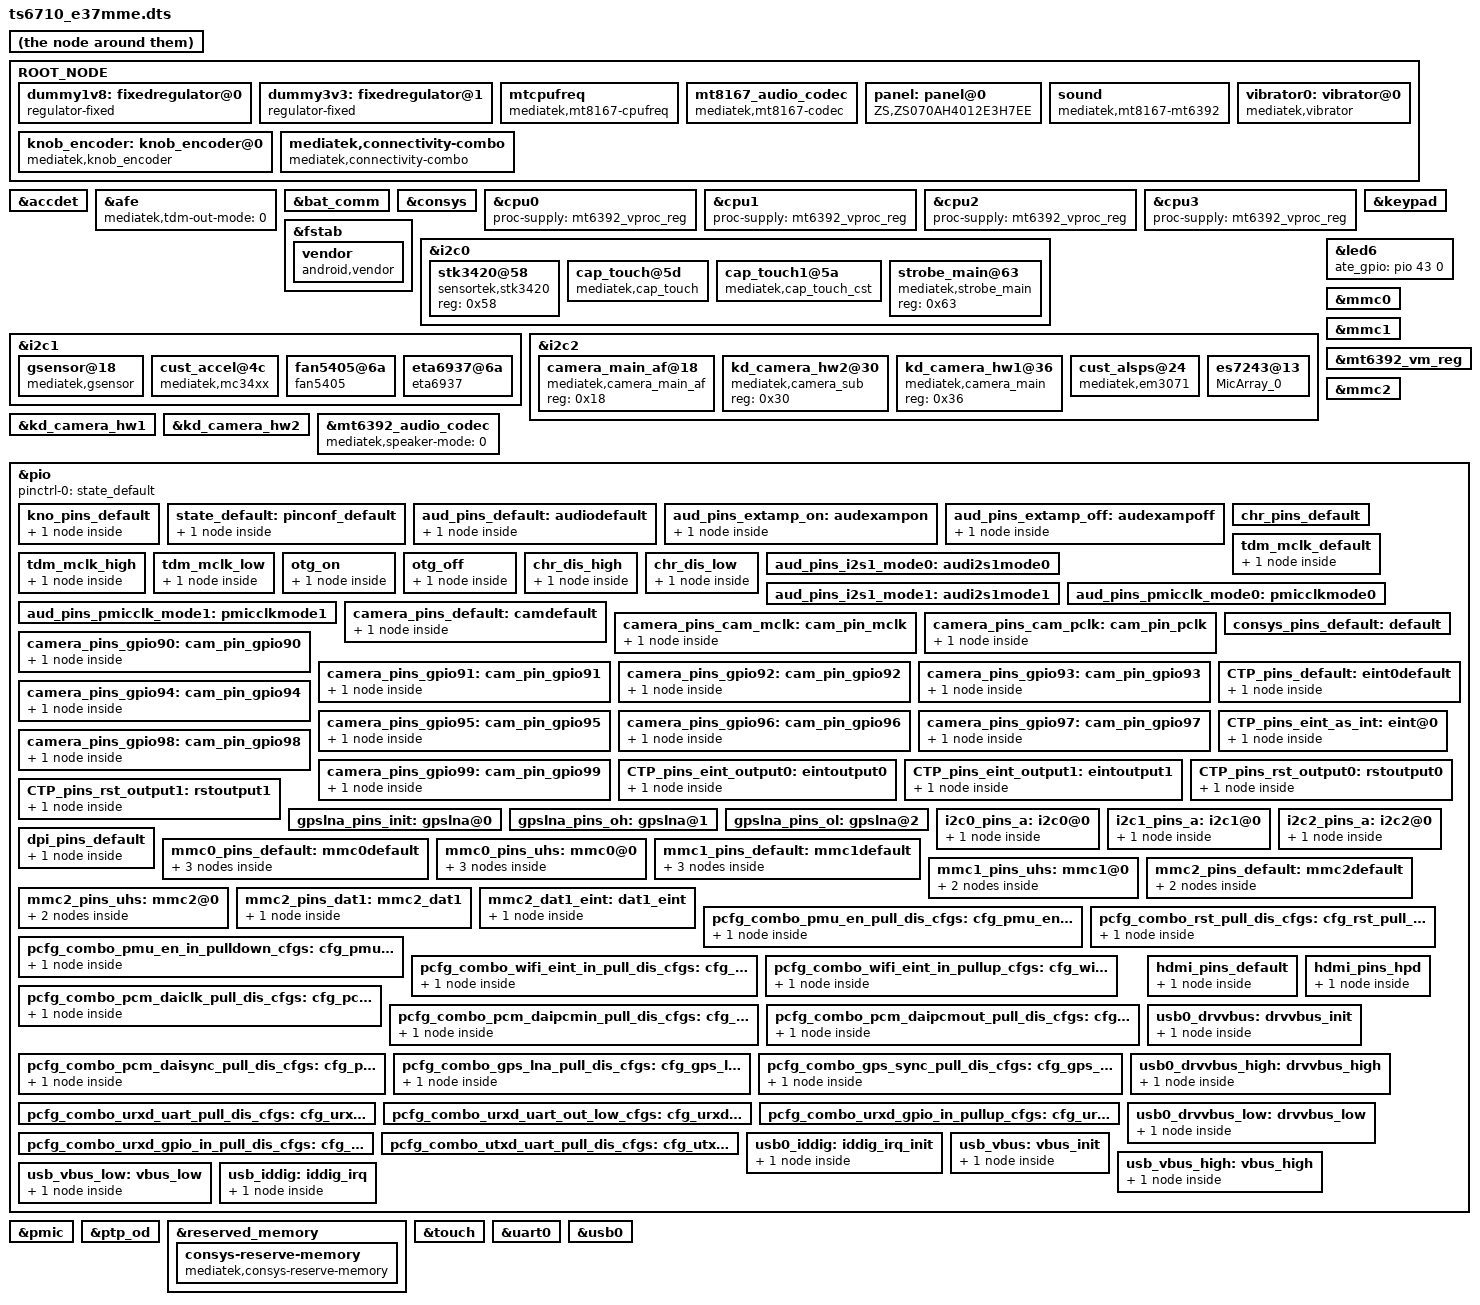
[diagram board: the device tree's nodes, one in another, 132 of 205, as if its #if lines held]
/*
 * Copyright (c) 2014-2015 MediaTek Inc.
 *
 * This program is free software; you can redistribute it and/or modify
 * it under the terms of the GNU General Public License version 2 as
 * published by the Free Software Foundation.
 *
 * This program is distributed in the hope that it will be useful,
 * MERCHANTABILITY or FITNESS FOR A PARTICULAR PURPOSE.  See the
 * GNU General Public License for more details.
 */

#include <generated/autoconf.h>
/dts-v1/;

#ifdef CONFIG_MTK_DTBO_FEATURE
/plugin/;
#include <dt-bindings/clock/mt8167-clk.h>
#include <dt-bindings/interrupt-controller/irq.h>
#include <dt-bindings/interrupt-controller/arm-gic.h>
#include "mt8167-pinfunc.h"
#define ROOT_NODE &odm
#else
#include "mt8167.dtsi"
#include "mt6392.dtsi"
#define ROOT_NODE /
#endif
#include "ts6710_e37mme_bat_setting.dtsi"
#include <dt-bindings/gpio/gpio.h>

ROOT_NODE {
	dummy1v8: fixedregulator@0 {
		compatible = "regulator-fixed";
		regulator-name = "mmc_io";
		regulator-min-microvolt = <1800000>;
		regulator-max-microvolt = <1800000>;
		regulator-always-on;
	};

	dummy3v3: fixedregulator@1 {
		compatible = "regulator-fixed";
		regulator-name = "mmc_power";
		regulator-min-microvolt = <3300000>;
		regulator-max-microvolt = <3300000>;
		regulator-always-on;
	};

	mtcpufreq {
		compatible = "mediatek,mt8167-cpufreq";
	};

	mt8167_audio_codec: mt8167_audio_codec {
		compatible = "mediatek,mt8167-codec";
		clocks = <&topckgen CLK_TOP_AUDIO>;
		clock-names = "bus";
		mediatek,afe-regmap = <&afe>;
		mediatek,apmixedsys-regmap = <&apmixedsys>;
		mediatek,dmic-wire-mode = <1>; /* 0(ONE_WIRE) 1(TWO_WIRE) */
		mediatek,headphone-cap-sel = <1>; /* 0(10UF) 1(22UF) 2(33UF) 3(47UF) */
	};

	panel: panel@0 {
		compatible = "ZS,ZS070AH4012E3H7EE";
		pinctrl-names = "default";
		pinctrl-0 = <&dpi_pins_default>;
		gpio_lcd_pwr = <&pio 50 0>;
		gpio_lcd_rst = <&pio 66 0>;
		reg-lcm-supply = <&mt6392_vgp2_reg>;
		status = "okay";
	};

	sound: sound {
		compatible = "mediatek,mt8167-mt6392";
		mediatek,platform = <&afe>;
		mediatek,hp-spk-amp-warmup-time-us = <40000>;
		pinctrl-names = "default", "extamp_on", "extamp_off";
		pinctrl-0 = <&aud_pins_default>;
		pinctrl-1 = <&aud_pins_extamp_on>;
		pinctrl-2 = <&aud_pins_extamp_off>;
		status = "okay";
	};

	vibrator0:vibrator@0 {
		compatible = "mediatek,vibrator";
		vib_timer = <25>;
		vib_limit = <9>;
		vib_vol= <5>;
	};
	
	knob_encoder:knob_encoder@0 {
		compatible = "mediatek,knob_encoder";
		pinctrl-names = "default";
		pinctrl-0 = <&kno_pins_default>;
		signal-a-gpio = <&pio 19 2>;
        signal-b-gpio = <&pio 20 2>;
	};
   
/* Connectivity */
	mediatek,connectivity-combo {
		compatible = "mediatek,connectivity-combo";
		gpio_combo_pmu_en_pin = <&pio 1 0>;	/* GPIO_COMBO_PMU_EN_PIN */
		gpio_combo_rst_pin = <&pio 7 0>;	/* GPIO_COMBO_RST_PIN pin */
		//gpio_combo_bgf_eint_pin = <&pio 5 0>;	/* GPIO_COMBO_RST_PIN pin */
		gpio_wifi_eint_pin = <&pio 5 0>;	/* GPIO_WIFI_EINT_PIN */
		gpio_pcm_daiclk_pin = <&pio 36 0>;	/* GPIO_PCM_DAICLK_PIN */
		gpio_pcm_daipcmin_pin = <&pio 38 0>;	/* GPIO_PCM_DAIPCMIN_PIN */
		gpio_pcm_daipcmout_pin = <&pio 39 0>;	/* GPIO_PCM_DAIPCMOUT_PIN */
		gpio_pcm_daisync_pin = <&pio 37 0>;	    /* GPIO_PCM_DAISYNC_PIN */
		gpio_gps_sync_pin = <&pio 4 0>;		/* GPIO_GPS_SYNC_PIN */
		gpio_gps_lna_pin = <&pio 3 0>;		/* GPIO_GPS_LNA_PIN */
	//	gpio_combo_urxd_pin = <&pio 64 0>;	/* GPIO_COMBO_URXD_PIN */
	//	gpio_combo_utxd_pin = <&pio 65 0>;	/* GPIO_COMBO_UTXD_PIN */
		pinctrl-names = "gpio_pmu_en_pull_dis",
			"gpio_pmu_en_in_pulldown",
			"gpio_rst_pull_dis",
			"gpio_wifi_eint_in_pull_dis",
			"gpio_wifi_eint_in_pullup",
			"gpio_pcm_daiclk_pull_dis",
			"gpio_pcm_daipcmin_pull_dis",
			"gpio_pcm_daipcmout_pull_dis",
			"gpio_pcm_daisync_pull_dis",
			"gpio_gps_lna_pull_dis",
			"gpio_gps_sync_pull_dis",
			"gpio_urxd_uart_pull_dis",
			"gpio_urxd_gpio_in_pullup",
			"gpio_urxd_uart_out_low",
			"gpio_urxd_gpio_in_pull_dis",
			"gpio_utxd_uart_pull_dis";
		pinctrl-0 = <&pcfg_combo_pmu_en_pull_dis_cfgs>;
		pinctrl-1 = <&pcfg_combo_pmu_en_in_pulldown_cfgs>;
		pinctrl-2 = <&pcfg_combo_rst_pull_dis_cfgs>;
		pinctrl-3 = <&pcfg_combo_wifi_eint_in_pull_dis_cfgs>;
		pinctrl-4 = <&pcfg_combo_wifi_eint_in_pullup_cfgs>;
		pinctrl-5 = <&pcfg_combo_pcm_daiclk_pull_dis_cfgs>;
		pinctrl-6 = <&pcfg_combo_pcm_daipcmin_pull_dis_cfgs>;
		pinctrl-7 = <&pcfg_combo_pcm_daipcmout_pull_dis_cfgs>;
		pinctrl-8 = <&pcfg_combo_pcm_daisync_pull_dis_cfgs>;
		pinctrl-9 = <&pcfg_combo_gps_lna_pull_dis_cfgs>;
		pinctrl-10 = <&pcfg_combo_gps_sync_pull_dis_cfgs>;
		pinctrl-11= <&pcfg_combo_urxd_uart_pull_dis_cfgs>;
		pinctrl-12= <&pcfg_combo_urxd_gpio_in_pullup_cfgs>;
		pinctrl-13= <&pcfg_combo_urxd_uart_out_low_cfgs>;
		pinctrl-14 = <&pcfg_combo_urxd_gpio_in_pull_dis_cfgs>;
		pinctrl-15 = <&pcfg_combo_utxd_uart_pull_dis_cfgs>;
		interrupt-parent = <&pio>;
		interrupts = < 5 IRQ_TYPE_LEVEL_LOW >;	/* WIFI EINT num is 1 active low level-sensitive */
		status = "okay";
	};
};

&accdet {
	mediatek,apmixedsys-regmap = <&apmixedsys>;
	/*interrupts-extended = <&sysirq GIC_SPI 152 IRQ_TYPE_LEVEL_LOW>,
				<&pio 19 IRQ_TYPE_LEVEL_LOW>;
	eint-debounce = <256000>;
	accdet-gpio = <&pio 19 0>;*/
	accdet-mic-vol = <0>;
	headset-mode-setting = <0x500 0x500 1 0x1f0 0x800 0x800 0x20>;
	accdet-plugout-debounce = <20>;
	/*1:ACC mode, 2:low cost without in bias, 6:low cost with in bias*/
	accdet-mic-mode = <1>;
	status = "okay";
};

&afe {
	/* 0(HDMI) 1(I2S) 2(TDM) */
	mediatek,tdm-out-mode = <0>;
};

&bat_comm {
	interrupt-parent = <&pmic>;
	interrupts = <10 IRQ_TYPE_LEVEL_HIGH>;
};

&consys {
	pinctrl-names = "default", "gps_lna_state_init", "gps_lna_state_oh", "gps_lna_state_ol";
	pinctrl-0 = <&consys_pins_default>;
	pinctrl-1 = <&gpslna_pins_init>;
	pinctrl-2 = <&gpslna_pins_oh>;
	pinctrl-3 = <&gpslna_pins_ol>;
	vcn18-supply = <&mt6392_vcn18_reg>;
	vcn35-supply = <&mt6392_vcn35_reg>;
	status = "okay";
};

&cpu0 {
	proc-supply = <&mt6392_vproc_reg>;
};

&cpu1 {
	proc-supply = <&mt6392_vproc_reg>;
};

&cpu2 {
	proc-supply = <&mt6392_vproc_reg>;
};

&cpu3 {
	proc-supply = <&mt6392_vproc_reg>;
};

&fstab {
	vendor {
		compatible = "android,vendor";
		dev = "/dev/block/platform/soc/11120000.mmc/by-name/vendor";
		type = "ext4";
		mnt_flags = "ro";
		fsmgr_flags = "wait,verify";
	};
};


&i2c0 {
/*
	clock-div = <2>;
	clock-frequency = <400000>;
	pinctrl-names = "default";
	pinctrl-0 = <&i2c0_pins_a>;
	status = "okay";
*/
	clock-div = <2>;
	pinctrl-names = "default";
	pinctrl-0 = <&i2c0_pins_a>;
	status = "okay";
	
	stk3420@58 {
		compatible = "sensortek,stk3420";
		reg = <0x58>;
	};

	cap_touch@5d {
		compatible = "mediatek,cap_touch";
		reg = <0x5d>;
		interrupt-parent = <&pio>;
		interrupts = <100 IRQ_TYPE_EDGE_FALLING>;
		int-gpio = <&pio 100 0>;
		rst-gpio = <&pio 101 0>;
	};
	cap_touch1@5a {
		compatible = "mediatek,cap_touch_cst";
		reg = <0x5a>;
		interrupt-parent = <&pio>;
		interrupts = <100 IRQ_TYPE_EDGE_FALLING>;
	};

	strobe_main@63 {
		compatible = "mediatek,strobe_main";
		reg = <0x63>;
	};
};

&i2c1 {
	clock-div = <2>;
	pinctrl-names = "default";
	pinctrl-0 = <&i2c1_pins_a>;
	status = "okay";

	gsensor@18 {
        compatible = "mediatek,gsensor";
        reg = <0x18>;
		direction = <7>;/*7 ,5,*/
        };
		
	cust_accel@4c {
        compatible = "mediatek,mc34xx";
        reg = <0x4c>;
		direction = <7>;/*7 ,5,*/
	};
	
	fan5405@6a {
		status = "okay";
		compatible = "fan5405";
		reg = <0x6a>;
		pinctrl-names = "default", "otg_on", "otg_off","chr_dis_high","chr_dis_low";
		pinctrl-0 = <&chr_pins_default>;
		pinctrl-1 = <&otg_on>;
		pinctrl-2 = <&otg_off>;
	    pinctrl-3 = <&chr_dis_high>;
		pinctrl-4 = <&chr_dis_low>;
		//otg-gpio = <&pio 65 0>;
		//chr_dis_gpio = <&pio 15 0>;
	};
	#ifdef CONFIG_MTK_ETA6937_SUPPORT
	eta6937@6a {
	    status = "okay";
		compatible = "eta6937";
		reg = <0x6a>;
		pinctrl-names = "default", "otg_on", "otg_off","chr_dis_high","chr_dis_low";
		pinctrl-0 = <&chr_pins_default>;
		pinctrl-1 = <&otg_on>;
		pinctrl-2 = <&otg_off>;
	    pinctrl-3 = <&chr_dis_high>;
		pinctrl-4 = <&chr_dis_low>;
	};
	#endif
};

&i2c2 {
	clock-div = <2>;
	pinctrl-names = "default";
	pinctrl-0 = <&i2c2_pins_a>;
	status = "okay";
	camera_main_af@18 {
		compatible = "mediatek,camera_main_af";
		reg = <0x18>;
	};

	kd_camera_hw2@30 {
		compatible = "mediatek,camera_sub";
		reg = <0x30>;
	};

	kd_camera_hw1@36 {
		compatible = "mediatek,camera_main";
		reg = <0x36>;
	};
	
	cust_alsps@24 {
		compatible				= "mediatek,em3071";
		i2c_num					= <2>;
		i2c_addr				= <0x24 0 0 0>;
		reg = <0x24>;
		polling_mode_ps			= <1>;
		polling_mode_als		= <1>;
		power_id				= <0xffff>;
		power_vol				= <0>;
/* Total has 15 level*/
		als_level	= <5 12 20 30 100 300 400 500 800 1500 2000 2800 3200 3500 4000>;
/*  Total has 16 range*/
		als_value	= <1 40 90 160 225 320 500 640 800 1000 1280 2600 4000 9000 10240 10240>;
		ps_threshold_high		=  <35>;	/*90*/
		ps_threshold_low		=  <40>;
		is_batch_supported_ps	= <0>;
		is_batch_supported_als	= <0>;
		};
		
		es7243@13 {
                compatible = "MicArray_0";
                reg = <0x13>;
				es-power-supply = <&mt6392_vcamaf_reg>;
				pinctrl-names = "default", "mclk_high", "mclk_low";
		        pinctrl-0 = <&tdm_mclk_default>;
		        pinctrl-1 = <&tdm_mclk_high>;
		        pinctrl-2 = <&tdm_mclk_low>;
        };

};

/* Main Cam */
&kd_camera_hw1 {
	reg-vcama-supply = <&mt6392_vcama_reg>;		/* AVDD */
	reg-vcamd-supply = <&mt6392_vcamd_reg>;		/* DVDD */
	reg-vcamio-supply = <&mt6392_vcamio_reg>;	/* DOVDD */
	//reg-vcamaf-supply = <&mt6392_vcamaf_reg>;	/* AFVDD */

	pinctrl-names = "default",
		"cam_mclk", "cam_pclk",
		"cam_gpio90",  "cam_gpio91", "cam_gpio92", "cam_gpio93",  "cam_gpio94",
		"cam_gpio95",  "cam_gpio96", "cam_gpio97", "cam_gpio98",  "cam_gpio99";

	pinctrl-0 = <&camera_pins_default>;
	pinctrl-1 = <&camera_pins_cam_mclk>;
	pinctrl-2 = <&camera_pins_cam_pclk>;
	pinctrl-3 = <&camera_pins_gpio90>;
	pinctrl-4 = <&camera_pins_gpio91>;
	pinctrl-5 = <&camera_pins_gpio92>;
	pinctrl-6 = <&camera_pins_gpio93>;
	pinctrl-7 = <&camera_pins_gpio94>;
	pinctrl-8 = <&camera_pins_gpio95>;
	pinctrl-9 = <&camera_pins_gpio96>;
	pinctrl-10 = <&camera_pins_gpio97>;
	pinctrl-11 = <&camera_pins_gpio98>;
	pinctrl-12 = <&camera_pins_gpio99>;

	cam0_rst = <&pio 10 0>;
	cam0_pdn = <&pio 11 0>;
	cam1_rst = <&pio 23 0>;
	cam1_pdn = <&pio 12 0>;
	status = "okay";
};

/* Sub Cam */
/* Same power pins as Main, actually, it can be commented */
&kd_camera_hw2{
	reg-vcama-supply = <&mt6392_vcama_reg>;		/* AVDD */
	reg-vcamd-supply = <&mt6392_vcamd_reg>;		/* DVDD */
	reg-vcamio-supply = <&mt6392_vcamio_reg>;	/* DOVDD */
	//reg-vcamaf-supply = <&mt6392_vcamaf_reg>;	/* AFVDD */
};

&keypad {


	mediatek,kpd-key-debounce = <1024>;
	mediatek,kpd-sw-pwrkey = <116>;
	mediatek,kpd-hw-pwrkey = <8>;
	mediatek,kpd-sw-rstkey  = <0>;
	mediatek,kpd-hw-rstkey = <17>;
	mediatek,kpd-use-extend-type = <0>;
	/*HW Keycode [0~71] -> Linux Keycode*/
	mediatek,kpd-hw-map-num = <72>;
	mediatek,kpd-hw-init-map = <115 0 0 0 0 0 0 0 0 0 0 0 0 0 0 0 0 0 0 0 0 0 0 0
			0 0 0 0 0 0 0 0 0 0 0 0 0 0 0 0 0 0 0 0 0 0 0 0
			0 0 0 0 0 0 0 0 0 0 0 0 0 0 0 0 0 0 0 0 0 0 0 0 >;
	mediatek,kpd-pwrkey-eint-gpio = <0>;
	mediatek,kpd-pwkey-gpio-din  = <0>;
	mediatek,kpd-hw-dl-key0 = <0>;
	mediatek,kpd-hw-dl-key1 = <17>;
	mediatek,kpd-hw-dl-key2 = <8>;
	mediatek,kpd-hw-recovery-key = <17>;
	mediatek,kpd-hw-factory-key  = <0>;
};

&led6 {
	ate_gpio = <&pio 43 0>;
};

&mmc0 {
	pinctrl-names = "default", "state_uhs";
	pinctrl-0 = <&mmc0_pins_default>;
	pinctrl-1 = <&mmc0_pins_uhs>;
	status = "okay";
	bus-width = <8>;
	max-frequency = <200000000>;
	cap-mmc-highspeed;
	mmc-hs200-1_8v;
	cap-mmc-hw-reset;
	vmmc-supply = <&mt6392_vemc3v3_reg>;
	vqmmc-supply = <&mt6392_vio18_reg>;
	non-removable;
};

&mmc1 {
	pinctrl-names = "default", "state_uhs";
	pinctrl-0 = <&mmc1_pins_default>;
	pinctrl-1 = <&mmc1_pins_uhs>;
	status = "okay";
	bus-width = <4>;
	max-frequency = <50000000>;
	cap-sd-highspeed;
	sd-uhs-sdr50;
	sd-uhs-sdr104;
	cd-gpios = <&pio 65 GPIO_ACTIVE_LOW>;
	vmmc-supply = <&mt6392_vmch_reg>;
	vqmmc-supply = <&mt6392_vmc_reg>;
};

&mt6392_audio_codec {
	mediatek,speaker-mode = <0>; /* 0(CLASSD) 1(CLASSAB) */
	status = "okay";
};

&mt6392_vm_reg {
	regulator-always-on;
	regulator-boot-on;
};

&mmc2 {
	pinctrl-names = "default", "state_uhs", "state_dat1", "state_eint";
	pinctrl-0 = <&mmc2_pins_default>;
	pinctrl-1 = <&mmc2_pins_uhs>;
	pinctrl-2 = <&mmc2_pins_dat1>;
	pinctrl-3 = <&mmc2_dat1_eint>;
	eint-gpios = <&pio 71 0>;
	status = "okay";
	bus-width = <4>;
	max-frequency = <200000000>;
	cap-sd-highspeed;
	sd-uhs-sdr50;
	sd-uhs-sdr104;
};


&pio {
	pinctrl-names = "default";
	pinctrl-0 = <&state_default>;

	kno_pins_default:kno_pins_default {
	pins_cmd_dat {
			pinmux = <MT8167_PIN_19_EINT19__FUNC_GPIO19>,
				     <MT8167_PIN_20_EINT20__FUNC_GPIO20>;
				 bias-pull-up;
		};
	};
	state_default:pinconf_default {
	pins_cmd_dat {
			pinmux = <MT8167_PIN_15_EINT15__FUNC_TDM_RX_BCK>,
				     <MT8167_PIN_16_EINT16__FUNC_TDM_RX_LRCK>,
				     <MT8167_PIN_17_EINT17__FUNC_TDM_RX_DI>;
				 bias-pull-up;
		};
	};

		aud_pins_default: audiodefault {
			pins_extamp_default {
			pins = <MT8167_PIN_55_I2S_DATA_IN__FUNC_GPIO55>;
			slew-rate = <1>;
			output-low;
		};
	};

	aud_pins_extamp_on: audexampon {
	pins_cmd_dat {
			pins = <MT8167_PIN_55_I2S_DATA_IN__FUNC_GPIO55>;/**/
			slew-rate = <1>;
			output-high;
		};
	};

	aud_pins_extamp_off: audexampoff {
	pins_cmd_dat {
			pins = <MT8167_PIN_55_I2S_DATA_IN__FUNC_GPIO55>;/**/
			slew-rate = <1>;
			output-low;
		};
	};
   chr_pins_default: chr_pins_default {
			
	};

  tdm_mclk_default:tdm_mclk_default {
	pins_cmd_dat {
			pinmux = <MT8167_PIN_14_EINT14__FUNC_TDM_RX_MCK>;
				 bias-pull-up;
		};
	};
  tdm_mclk_high:tdm_mclk_high {
	pins_cmd_dat {
		pins = <MT8167_PIN_14_EINT14__FUNC_GPIO14>;/**/
			slew-rate = <1>;
			output-high;
		};
	};
  tdm_mclk_low:tdm_mclk_low {
	pins_cmd_dat {
		pins = <MT8167_PIN_14_EINT14__FUNC_GPIO14>;/**/
			slew-rate = <1>;
			output-low;
		};
	};
	otg_on: otg_on {
	pins_cmd_dat {
			pins = <MT8167_PIN_65_UTXD1__FUNC_GPIO65>;/**/
			slew-rate = <1>;
			output-high;
		};
	};

	otg_off: otg_off {
	pins_cmd_dat {
			pins = <MT8167_PIN_65_UTXD1__FUNC_GPIO65>;/**/
			slew-rate = <1>;
			output-low;
		};
	};
	chr_dis_high: chr_dis_high {
	pins_cmd_dat {
			pins = <MT8167_PIN_13_EINT13__FUNC_GPIO13>;/**/
			slew-rate = <1>;
			output-high;
		};
	};

	chr_dis_low: chr_dis_low {
	pins_cmd_dat {
			pins = <MT8167_PIN_13_EINT13__FUNC_GPIO13>;/**/
			slew-rate = <1>;
			output-low;
		};
	};
	aud_pins_i2s1_mode0: audi2s1mode0 {
	};

	aud_pins_i2s1_mode1: audi2s1mode1 {
	};

	aud_pins_pmicclk_mode0: pmicclkmode0 {
	};

	aud_pins_pmicclk_mode1: pmicclkmode1 {
	};

	/* CAMERA GPIO standardization */
	/* default mode */
	camera_pins_default: camdefault {
	pins_cmd_dat {
			pinmux = <MT8167_PIN_102_CMMCLK__FUNC_CMMCLK>,
			         <MT8167_PIN_103_CMPCLK__FUNC_CMPCLK>,
					 <MT8167_PIN_84_RDN0__FUNC_RDN0>,
				     <MT8167_PIN_85_RDP0__FUNC_RDP0>,
				     <MT8167_PIN_86_RDN1__FUNC_RDN1>,
				     <MT8167_PIN_87_RDP1__FUNC_RDP1>,
				     <MT8167_PIN_88_RCN__FUNC_RCN>,
					 <MT8167_PIN_89_RCP__FUNC_RCP>,
				     <MT8167_PIN_90_RDN2__FUNC_RDN2>,
				     <MT8167_PIN_91_RDP2__FUNC_RDP2>,
				     <MT8167_PIN_94_RCN_A__FUNC_RCN_A>,
				     <MT8167_PIN_95_RCP_A__FUNC_RCP_A>,
				     <MT8167_PIN_96_RDN1_A__FUNC_RDN1_A>,
				     <MT8167_PIN_97_RDP1_A__FUNC_RDP1_A>,
				     <MT8167_PIN_98_RDN0_A__FUNC_RDN0_A>,
				     <MT8167_PIN_99_RDP0_A__FUNC_RDP0_A>;
				 
		};
	};

	camera_pins_cam_mclk: cam_pin_mclk {
		pins_cmd_dat {
			pins = <MT8167_PIN_102_CMMCLK__FUNC_CMMCLK>;
		};
	};

	camera_pins_cam_pclk: cam_pin_pclk {
		pins_cmd_dat {
			pins = <MT8167_PIN_103_CMPCLK__FUNC_CMPCLK>;
		};
	};

	camera_pins_gpio90: cam_pin_gpio90 {
		pins_cmd_dat {
			pins = <MT8167_PIN_90_RDN2__FUNC_CMDAT8>;
		};
	};

	camera_pins_gpio91: cam_pin_gpio91 {
		pins_cmd_dat {
			pins = <MT8167_PIN_91_RDP2__FUNC_CMDAT9>;
		};
	};

	camera_pins_gpio92: cam_pin_gpio92 {
		pins_cmd_dat {
			pins = <MT8167_PIN_92_RDN3__FUNC_CMDAT4>;
		};
	};

	camera_pins_gpio93: cam_pin_gpio93 {
		pins_cmd_dat {
			pins = <MT8167_PIN_93_RDP3__FUNC_CMDAT5>;
		};
	};

	camera_pins_gpio94: cam_pin_gpio94 {
		pins_cmd_dat {
			pins = <MT8167_PIN_94_RCN_A__FUNC_CMDAT6>;
		};
	};

	camera_pins_gpio95: cam_pin_gpio95 {
		pins_cmd_dat {
			pins = <MT8167_PIN_95_RCP_A__FUNC_CMDAT7>;
		};
	};

	camera_pins_gpio96: cam_pin_gpio96 {
		pins_cmd_dat {
			pins = <MT8167_PIN_96_RDN1_A__FUNC_CMDAT2>;
		};
	};

	camera_pins_gpio97: cam_pin_gpio97 {
		pins_cmd_dat {
			pins = <MT8167_PIN_97_RDP1_A__FUNC_CMDAT3>;
		};
	};

	camera_pins_gpio98: cam_pin_gpio98 {
		pins_cmd_dat {
			pins = <MT8167_PIN_98_RDN0_A__FUNC_CMHSYNC>;
		};
	};

	camera_pins_gpio99: cam_pin_gpio99 {
		pins_cmd_dat {
			pins = <MT8167_PIN_99_RDP0_A__FUNC_CMVSYNC>;
		};
	};

	/* CONSYS GPIO Settings - Start */
	consys_pins_default: default {

	};
	/* CONSYS GPIO Settings - End */

	CTP_pins_default: eint0default {
		pins_cmd_dat {
			pins = <MT8167_PIN_100_CMDAT0__FUNC_GPIO100>;
			slew-rate = <0>;
			bias-disable;
		};
	};

	CTP_pins_eint_as_int: eint@0 {
		pins_cmd_dat {
			pins = <MT8167_PIN_100_CMDAT0__FUNC_GPIO100>;
			slew-rate = <0>;
			bias-disable;
		};
	};

	CTP_pins_eint_output0: eintoutput0 {
		pins_cmd_dat {
			pins = <MT8167_PIN_100_CMDAT0__FUNC_GPIO100>;
			slew-rate = <1>;
			output-low;
		};
	};

	CTP_pins_eint_output1: eintoutput1 {
		pins_cmd_dat {
			pins = <MT8167_PIN_100_CMDAT0__FUNC_GPIO100>;
			slew-rate = <1>;
			output-high;
		};
	};

	CTP_pins_rst_output0: rstoutput0 {
		pins_cmd_dat {
			pins = <MT8167_PIN_101_CMDAT1__FUNC_GPIO101>;
			slew-rate = <1>;
			output-low;
		};
	};

	CTP_pins_rst_output1: rstoutput1 {
		pins_cmd_dat {
			pins = <MT8167_PIN_101_CMDAT1__FUNC_GPIO101>;
			slew-rate = <1>;
			output-high;
		};
	};

	/* CONSYS GPIO Settings - Start */
	gpslna_pins_init: gpslna@0 {
	};

	gpslna_pins_oh: gpslna@1 {
	};

	gpslna_pins_ol: gpslna@2 {
	};
	/* CONSYS GPIO Settings - End */

	i2c0_pins_a: i2c0@0 {
		pins1 {
			pinmux = <MT8167_PIN_58_SDA0__FUNC_SDA0_0>,
				 <MT8167_PIN_59_SCL0__FUNC_SCL0_0>;
			bias-disable;
		};
	};

	i2c1_pins_a: i2c1@0 {
		pins1 {
			pinmux = <MT8167_PIN_52_SDA1__FUNC_SDA1_0>,
				 <MT8167_PIN_53_SCL1__FUNC_SCL1_0>;
			bias-disable;
		};
	};

	i2c2_pins_a: i2c2@0 {
		pins1 {
			pinmux = <MT8167_PIN_60_SDA2__FUNC_SDA2_0>,
				 <MT8167_PIN_61_SCL2__FUNC_SCL2_0>;
			bias-disable;
		};
	};

	dpi_pins_default: dpi_pins_default {
		pins_cmd_dat {
		
		};
	};

	mmc0_pins_default: mmc0default {
		pins_cmd_dat {
			pinmux = <MT8167_PIN_120_MSDC0_DAT0__FUNC_MSDC0_DAT0>,
				<MT8167_PIN_119_MSDC0_DAT1__FUNC_MSDC0_DAT1>,
				<MT8167_PIN_118_MSDC0_DAT2__FUNC_MSDC0_DAT2>,
				<MT8167_PIN_117_MSDC0_DAT3__FUNC_MSDC0_DAT3>,
				<MT8167_PIN_113_MSDC0_DAT4__FUNC_MSDC0_DAT4>,
				<MT8167_PIN_112_MSDC0_DAT5__FUNC_MSDC0_DAT5>,
				<MT8167_PIN_111_MSDC0_DAT6__FUNC_MSDC0_DAT6>,
				<MT8167_PIN_110_MSDC0_DAT7__FUNC_MSDC0_DAT7>,
				<MT8167_PIN_115_MSDC0_CMD__FUNC_MSDC0_CMD>;
			input-enable;
			bias-pull-up;
		};

		pins_clk {
			pinmux = <MT8167_PIN_116_MSDC0_CLK__FUNC_MSDC0_CLK>;
			bias-pull-down;
		};

		pins_rst {
			pinmux = <MT8167_PIN_114_MSDC0_RSTB__FUNC_MSDC0_RSTB>;
			bias-pull-up;
		};
	};

	mmc0_pins_uhs: mmc0@0{
		pins_cmd_dat {
			pinmux = <MT8167_PIN_120_MSDC0_DAT0__FUNC_MSDC0_DAT0>,
				<MT8167_PIN_119_MSDC0_DAT1__FUNC_MSDC0_DAT1>,
				<MT8167_PIN_118_MSDC0_DAT2__FUNC_MSDC0_DAT2>,
				<MT8167_PIN_117_MSDC0_DAT3__FUNC_MSDC0_DAT3>,
				<MT8167_PIN_113_MSDC0_DAT4__FUNC_MSDC0_DAT4>,
				<MT8167_PIN_112_MSDC0_DAT5__FUNC_MSDC0_DAT5>,
				<MT8167_PIN_111_MSDC0_DAT6__FUNC_MSDC0_DAT6>,
				<MT8167_PIN_110_MSDC0_DAT7__FUNC_MSDC0_DAT7>,
				<MT8167_PIN_115_MSDC0_CMD__FUNC_MSDC0_CMD>;
			input-enable;
			drive-strength = <MTK_DRIVE_6mA>;
			bias-pull-up = <MTK_PUPD_SET_R1R0_01>;
		};

		pins_clk {
			pinmux = <MT8167_PIN_116_MSDC0_CLK__FUNC_MSDC0_CLK>;
			drive-strength = <MTK_DRIVE_8mA>;
			bias-pull-down = <MTK_PUPD_SET_R1R0_10>;
		};

		pins_rst {
			pinmux = <MT8167_PIN_114_MSDC0_RSTB__FUNC_MSDC0_RSTB>;
			bias-pull-up;
		};
	};

	mmc1_pins_default: mmc1default {
		pins_cmd_dat {
			pinmux = <MT8167_PIN_106_MSDC1_DAT0__FUNC_MSDC1_DAT0>,
				<MT8167_PIN_107_MSDC1_DAT1__FUNC_MSDC1_DAT1>,
				<MT8167_PIN_108_MSDC1_DAT2__FUNC_MSDC1_DAT2>,
				<MT8167_PIN_109_MSDC1_DAT3__FUNC_MSDC1_DAT3>,
				<MT8167_PIN_104_MSDC1_CMD__FUNC_MSDC1_CMD>;
			input-enable;
			drive-strength = <MTK_DRIVE_8mA>;
			bias-pull-up = <MTK_PUPD_SET_R1R0_01>;
		};

		pins_clk {
			pinmux = <MT8167_PIN_105_MSDC1_CLK__FUNC_MSDC1_CLK>;
			drive-strength = <MTK_DRIVE_8mA>;
			bias-pull-down = <MTK_PUPD_SET_R1R0_10>;
		};

		pins_insert {
	
		};
	};

	mmc1_pins_uhs: mmc1@0 {
		pins_cmd_dat {
			pinmux = <MT8167_PIN_106_MSDC1_DAT0__FUNC_MSDC1_DAT0>,
				<MT8167_PIN_107_MSDC1_DAT1__FUNC_MSDC1_DAT1>,
				<MT8167_PIN_108_MSDC1_DAT2__FUNC_MSDC1_DAT2>,
				<MT8167_PIN_109_MSDC1_DAT3__FUNC_MSDC1_DAT3>,
				<MT8167_PIN_104_MSDC1_CMD__FUNC_MSDC1_CMD>;
			input-enable;
			drive-strength = <MTK_DRIVE_8mA>;
			bias-pull-up = <MTK_PUPD_SET_R1R0_01>;
		};

		pins_clk {
			pinmux = <MT8167_PIN_105_MSDC1_CLK__FUNC_MSDC1_CLK>;
			drive-strength = <MTK_DRIVE_8mA>;
			bias-pull-down = <MTK_PUPD_SET_R1R0_10>;
		};
	};

	mmc2_pins_default: mmc2default {
		pins_cmd_dat {
			pinmux = <MT8167_PIN_70_MSDC2_DAT0__FUNC_MSDC2_DAT0>,
				<MT8167_PIN_71_MSDC2_DAT1__FUNC_MSDC2_DAT1>,
				<MT8167_PIN_72_MSDC2_DAT2__FUNC_MSDC2_DAT2>,
				<MT8167_PIN_73_MSDC2_DAT3__FUNC_MSDC2_DAT3>,
				<MT8167_PIN_68_MSDC2_CMD__FUNC_MSDC2_CMD>;
			input-enable;
			drive-strength = <MTK_DRIVE_8mA>;
			bias-pull-up = <MTK_PUPD_SET_R1R0_10>;
		};

		pins_clk {
			pinmux = <MT8167_PIN_69_MSDC2_CLK__FUNC_MSDC2_CLK>;
			drive-strength = <MTK_DRIVE_8mA>;
			bias-pull-down = <MTK_PUPD_SET_R1R0_10>;
		};
	};

	mmc2_pins_uhs: mmc2@0 {
		pins_cmd_dat {
			pinmux = <MT8167_PIN_70_MSDC2_DAT0__FUNC_MSDC2_DAT0>,
				<MT8167_PIN_71_MSDC2_DAT1__FUNC_MSDC2_DAT1>,
				<MT8167_PIN_72_MSDC2_DAT2__FUNC_MSDC2_DAT2>,
				<MT8167_PIN_73_MSDC2_DAT3__FUNC_MSDC2_DAT3>,
				<MT8167_PIN_68_MSDC2_CMD__FUNC_MSDC2_CMD>;
			input-enable;
			drive-strength = <MTK_DRIVE_8mA>;
			bias-pull-up = <MTK_PUPD_SET_R1R0_10>;
		};

		pins_clk {
			pinmux = <MT8167_PIN_69_MSDC2_CLK__FUNC_MSDC2_CLK>;
			drive-strength = <MTK_DRIVE_8mA>;
			bias-pull-down = <MTK_PUPD_SET_R1R0_10>;
		};
	};

	mmc2_pins_dat1: mmc2_dat1 {
		pins_dat1 {
			pinmux = <MT8167_PIN_71_MSDC2_DAT1__FUNC_MSDC2_DAT1>;
			input-enable;
			drive-strength = <MTK_DRIVE_8mA>;
			bias-pull-up = <MTK_PUPD_SET_R1R0_10>;
		};
	};

	mmc2_dat1_eint: dat1_eint {
		pins_dat1 {
			pinmux = <MT8167_PIN_71_MSDC2_DAT1__FUNC_GPIO71>;
			input-enable;
			bias-pull-up = <MTK_PUPD_SET_R1R0_10>;
		};
	};

    /* Connectivity GPIO start */
	pcfg_combo_pmu_en_pull_dis_cfgs:cfg_pmu_en_pull_dis {
		combo_pins {
			pins = <MT8167_PIN_1_EINT1__FUNC_GPIO1>;
			bias-disable;
		};
	};

	pcfg_combo_pmu_en_in_pulldown_cfgs:cfg_pmu_en_in_pulldown {
		combo_pins {
			pins = <MT8167_PIN_1_EINT1__FUNC_GPIO1>;
			bias-pull-down;
		};
	};

	pcfg_combo_rst_pull_dis_cfgs:cfg_rst_pull_dis {
		combo_pins {
			pins = <MT8167_PIN_7_EINT7__FUNC_GPIO7>;
			bias-disable;
		};
	};

	pcfg_combo_wifi_eint_in_pull_dis_cfgs:cfg_wifi_eint_in_pull_dis {
		combo_pins {
			pins = <MT8167_PIN_5_EINT5__FUNC_GPIO5>;
			slew-rate = <0>;
			bias-disable;
		};
	};

	pcfg_combo_wifi_eint_in_pullup_cfgs:cfg_wifi_eint_in_pullup {
		combo_pins {
			pins = <MT8167_PIN_5_EINT5__FUNC_GPIO5>;
			slew-rate = <0>;
			bias-pull-up = <00>;
		};
	};

	pcfg_combo_pcm_daiclk_pull_dis_cfgs:cfg_pcm_daiclk_pull_dis {
		combo_pins {
			pins = <MT8167_PIN_36_MRG_CLK__FUNC_PCM0_CLK>;
			bias-disable;
		};
	};

	pcfg_combo_pcm_daipcmin_pull_dis_cfgs:cfg_pcm_daipcmin_pull_dis {
		combo_pins {
			pins = <MT8167_PIN_38_MRG_DI__FUNC_PCM0_DI>;
			bias-disable;
		};
	};

	pcfg_combo_pcm_daipcmout_pull_dis_cfgs:cfg_pcm_daipcmout_pull_dis {
		combo_pins {
			pins = <MT8167_PIN_39_MRG_DO__FUNC_PCM0_DO>;
			bias-disable;
		};
	};

	pcfg_combo_pcm_daisync_pull_dis_cfgs:cfg_pcm_daisync_pull_dis {
		combo_pins {
			pins = <MT8167_PIN_37_MRG_SYNC__FUNC_PCM0_SYNC>;
			bias-disable;
		};
	};

	pcfg_combo_gps_lna_pull_dis_cfgs:cfg_gps_lna_pull_dis {
		combo_pins {
			pins = <MT8167_PIN_3_EINT3__FUNC_GPIO3>;
			bias-disable;
		};
	};

	pcfg_combo_gps_sync_pull_dis_cfgs:cfg_gps_sync_pull_dis {
		combo_pins {
			pins = <MT8167_PIN_4_EINT4__FUNC_GPIO4>;
			bias-disable;
		};
	};

	pcfg_combo_urxd_uart_pull_dis_cfgs:cfg_urxd_pull_dis {
		
	};

	pcfg_combo_urxd_uart_out_low_cfgs:cfg_urxd_out_low {
		
	};

	pcfg_combo_urxd_gpio_in_pullup_cfgs:cfg_urxd_in_pullup {
		
	};

	pcfg_combo_urxd_gpio_in_pull_dis_cfgs:cfg_urxd_in_pull_dis {
		
	};

	pcfg_combo_utxd_uart_pull_dis_cfgs:cfg_utxd_pull_dis {
		
	};
/* Connectivity GPIO end */

/* HDMI GPIO start */	
hdmi_pins_default: hdmi_pins_default {
		pins_cmd_dat {
		pinmux = <MT8167_PIN_121_CEC__FUNC_CEC>,
		         <MT8167_PIN_123_HDMISCK__FUNC_HDMISCK>,
                 <MT8167_PIN_124_HDMISD__FUNC_HDMISD>;				 
		};
	};

	hdmi_pins_hpd: hdmi_pins_hpd {
		pins_cmd_dat {
			pins = <MT8167_PIN_122_HTPLG__FUNC_HTPLG>;
			slew-rate = <0>;
			bias-pull-down;
		};
	};
/* HDMI GPIO end */	
/* Connectivity GPIO end */

/* USB GPIO start */
	usb0_drvvbus: drvvbus_init {
		pins_cmd_dat {
			pins = <MT8167_PIN_65_UTXD1__FUNC_GPIO65>;
			output-low;
		};
	};

	usb0_drvvbus_high: drvvbus_high {
		pins_cmd_dat {
			pins = <MT8167_PIN_65_UTXD1__FUNC_GPIO65>;
			slew-rate = <1>;
			output-high;
		};
	};

	usb0_drvvbus_low: drvvbus_low {
		pins_cmd_dat {
			pins = <MT8167_PIN_65_UTXD1__FUNC_GPIO65>;
			slew-rate = <1>;
			output-low;
		};
	};

	usb0_iddig: iddig_irq_init {
		pins_cmd_dat {
			pins = <MT8167_PIN_41_KPROW1__FUNC_IDDIG>;
			slew-rate = <0>;
			bias-pull-up = <00>;
		};
	};

	usb_vbus: vbus_init {
		pins_cmd_dat {
			pins = <MT8167_PIN_24_EINT24__FUNC_GPIO24>;
			output-high;
		};
	};

	usb_vbus_high: vbus_high {
		pins_cmd_dat {
			pins = <MT8167_PIN_24_EINT24__FUNC_GPIO24>;
			slew-rate = <1>;
			output-high;
		};
	};

	usb_vbus_low: vbus_low {
		pins_cmd_dat {
			pins = <MT8167_PIN_24_EINT24__FUNC_GPIO24>;
			slew-rate = <1>;
			output-low;
		};
	};

	usb_iddig: iddig_irq {
		pins_cmd_dat {
			pins = <MT8167_PIN_40_KPROW0__FUNC_GPIO40>;
			slew-rate = <0>;
			bias-pull-up = <00>;
		};
	};
/* USB GPIO end */
};

&pmic {
	interrupt-parent = <&pio>;
	interrupts = <28 IRQ_TYPE_LEVEL_HIGH>;
	interrupt-controller;
	#interrupt-cells = <2>;
};

&ptp_od {
	vproc-supply = <&mt6392_vproc_reg>;
	vcore-supply = <&mt6392_vcore_reg>;
};

&reserved_memory {
	#address-cells = <2>;
	#size-cells = <2>;
	ranges;

	consys-reserve-memory {
		compatible = "mediatek,consys-reserve-memory";
		no-map;
		size = <0 0x200000>;
		alignment = <0 0x200000>;
	};
};

&touch {
	vtouch-supply = <&mt6392_vgp1_reg>;
	tpd-resolution = <1024 600>;
	use-tpd-button = <0>;
	tpd-key-num = <3>;
	tpd-key-local= <139 172 158 0>;
	tpd-key-dim-local = <90 883 100 40 230 883 100 40 370 883 100 40 0 0 0 0>;
	tpd-max-touch-num = <5>;
	tpd-filter-enable = <1>;
	tpd-filter-pixel-density = <124>;
	tpd-filter-custom-prameters = <0 0 0 0 0 0 0 0 0 0 0 0>;
	tpd-filter-custom-speed = <0 0 0>;
	pinctrl-names = "default", "state_eint_as_int", "state_eint_output0", "state_eint_output1",
		"state_rst_output0", "state_rst_output1";
	pinctrl-0 = <&CTP_pins_default>;
	pinctrl-1 = <&CTP_pins_eint_as_int>;
	pinctrl-2 = <&CTP_pins_eint_output0>;
	pinctrl-3 = <&CTP_pins_eint_output1>;
	pinctrl-4 = <&CTP_pins_rst_output0>;
	pinctrl-5 = <&CTP_pins_rst_output1>;
	status = "okay";
};

&uart0 {
	status="okay";
};

&usb0 {
	pinctrl-names = "iddig_irq_init", "drvvbus_init", "drvvbus_low", "drvvbus_high";
	pinctrl-0 = <&usb0_iddig>;
	pinctrl-1 = <&usb0_drvvbus>;
	pinctrl-2 = <&usb0_drvvbus_low>;
	pinctrl-3 = <&usb0_drvvbus_high>;
	usb-power-supply = <&mt6392_vusb_reg>;
	status = "okay";
	/*drvvbus_gpio = <&pio 65 0>;*/
};


